# ESP32C3 register map
File version: 1.0
CPU: RISC-V RV32IMC single-core 1, little endian, no MPU, FPU, 3 interrupt priority bits
Registers are 32-bit, read-write, reset 0x0 unless marked. A register's access mark holds for its fields unless they carry their own. Offsets are from the block's base; [hi:lo] are bit positions; {n}, {i} and the like mark numbered series.

## EFUSE
Base 0x60008800
0x00 EFUSE_PGM_DATA0
  [31:0] EFUSE_WR_DIS
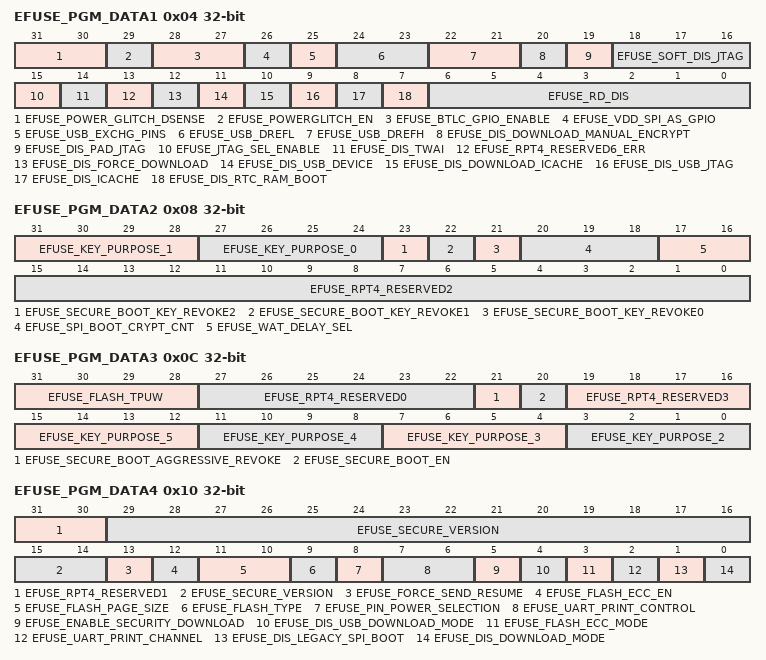
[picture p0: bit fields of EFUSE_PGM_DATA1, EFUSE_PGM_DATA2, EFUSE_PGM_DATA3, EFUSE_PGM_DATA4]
0x04 EFUSE_PGM_DATA1 access per field
  [31:30] EFUSE_POWER_GLITCH_DSENSE rw, [29] EFUSE_POWERGLITCH_EN rw, [28:27] EFUSE_BTLC_GPIO_ENABLE rw, [26] EFUSE_VDD_SPI_AS_GPIO rw, [25] EFUSE_USB_EXCHG_PINS rw, [24:23] EFUSE_USB_DREFL rw, [22:21] EFUSE_USB_DREFH rw, [20] EFUSE_DIS_DOWNLOAD_MANUAL_ENCRYPT rw, [19] EFUSE_DIS_PAD_JTAG rw, [18:16] EFUSE_SOFT_DIS_JTAG rw, [15] EFUSE_JTAG_SEL_ENABLE rw, [14] EFUSE_DIS_TWAI rw, [13] EFUSE_RPT4_RESERVED6_ERR ro, [12] EFUSE_DIS_FORCE_DOWNLOAD rw, [11] EFUSE_DIS_USB_DEVICE rw, [10] EFUSE_DIS_DOWNLOAD_ICACHE rw, [9] EFUSE_DIS_USB_JTAG rw, [8] EFUSE_DIS_ICACHE rw, [7] EFUSE_DIS_RTC_RAM_BOOT rw, [6:0] EFUSE_RD_DIS rw
0x08 EFUSE_PGM_DATA2 access per field
  [31:28] EFUSE_KEY_PURPOSE_1 rw, [27:24] EFUSE_KEY_PURPOSE_0 rw, [23] EFUSE_SECURE_BOOT_KEY_REVOKE2 rw, [22] EFUSE_SECURE_BOOT_KEY_REVOKE1 rw, [21] EFUSE_SECURE_BOOT_KEY_REVOKE0 rw, [20:18] EFUSE_SPI_BOOT_CRYPT_CNT rw, [17:16] EFUSE_WAT_DELAY_SEL rw, [15:0] EFUSE_RPT4_RESERVED2 ro
0x0C EFUSE_PGM_DATA3 access per field
  [31:28] EFUSE_FLASH_TPUW rw, [27:22] EFUSE_RPT4_RESERVED0 ro, [21] EFUSE_SECURE_BOOT_AGGRESSIVE_REVOKE rw, [20] EFUSE_SECURE_BOOT_EN rw, [19:16] EFUSE_RPT4_RESERVED3 ro, [4n-5:4n-8] EFUSE_KEY_PURPOSE_{n} rw (n=2..5)
0x10 EFUSE_PGM_DATA4 access per field
  [31:30] EFUSE_RPT4_RESERVED1 ro, [29:14] EFUSE_SECURE_VERSION rw, [13] EFUSE_FORCE_SEND_RESUME rw, [12] EFUSE_FLASH_ECC_EN rw, [11:10] EFUSE_FLASH_PAGE_SIZE rw, [9] EFUSE_FLASH_TYPE rw, [8] EFUSE_PIN_POWER_SELECTION rw, [7:6] EFUSE_UART_PRINT_CONTROL rw, [5] EFUSE_ENABLE_SECURITY_DOWNLOAD rw, [4] EFUSE_DIS_USB_DOWNLOAD_MODE rw, [3] EFUSE_FLASH_ECC_MODE rw, [2] EFUSE_UART_PRINT_CHANNEL rw, [1] EFUSE_DIS_LEGACY_SPI_BOOT rw, [0] EFUSE_DIS_DOWNLOAD_MODE rw
0x14 EFUSE_PGM_DATA5 ro
  [23:0] EFUSE_RPT4_RESERVED4
0x18 EFUSE_PGM_DATA6
  [31:0] EFUSE_PGM_DATA_6
0x1C EFUSE_PGM_DATA7
  [31:0] EFUSE_PGM_DATA_7
{0x20+4i} EFUSE_PGM_CHECK_VALUE{i} (i=0..2)
  [31:0] EFUSE_PGM_RS_DATA_{i}
0x2C EFUSE_RD_WR_DIS ro
  [31:0] EFUSE_WR_DIS
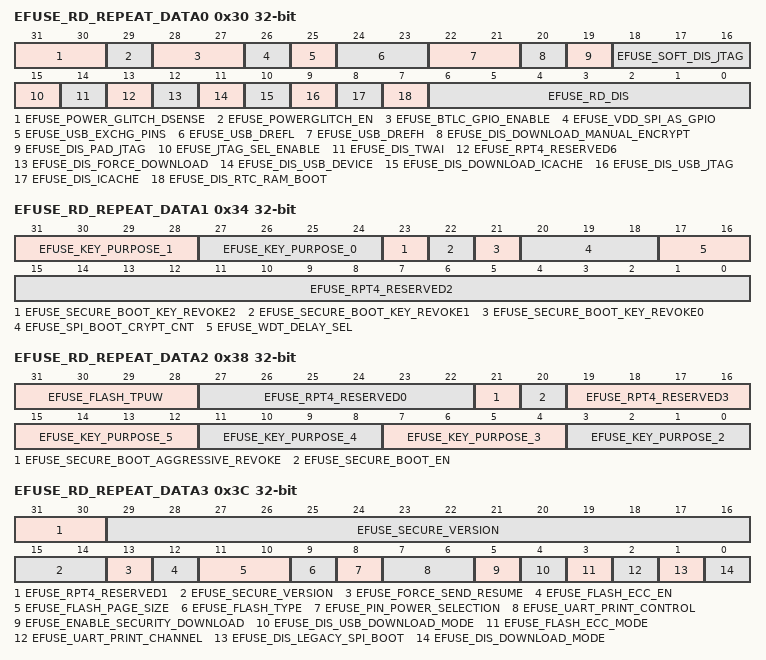
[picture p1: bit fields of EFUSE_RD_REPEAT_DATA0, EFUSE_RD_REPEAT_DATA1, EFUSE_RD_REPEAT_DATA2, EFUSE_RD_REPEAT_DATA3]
0x30 EFUSE_RD_REPEAT_DATA0 ro
  [31:30] EFUSE_POWER_GLITCH_DSENSE, [29] EFUSE_POWERGLITCH_EN, [28:27] EFUSE_BTLC_GPIO_ENABLE, [26] EFUSE_VDD_SPI_AS_GPIO, [25] EFUSE_USB_EXCHG_PINS, [24:23] EFUSE_USB_DREFL, [22:21] EFUSE_USB_DREFH, [20] EFUSE_DIS_DOWNLOAD_MANUAL_ENCRYPT, [19] EFUSE_DIS_PAD_JTAG, [18:16] EFUSE_SOFT_DIS_JTAG, [15] EFUSE_JTAG_SEL_ENABLE, [14] EFUSE_DIS_TWAI, [13] EFUSE_RPT4_RESERVED6, [12] EFUSE_DIS_FORCE_DOWNLOAD, [11] EFUSE_DIS_USB_DEVICE, [10] EFUSE_DIS_DOWNLOAD_ICACHE, [9] EFUSE_DIS_USB_JTAG, [8] EFUSE_DIS_ICACHE, [7] EFUSE_DIS_RTC_RAM_BOOT, [6:0] EFUSE_RD_DIS
0x34 EFUSE_RD_REPEAT_DATA1 ro
  [31:28] EFUSE_KEY_PURPOSE_1, [27:24] EFUSE_KEY_PURPOSE_0, [23] EFUSE_SECURE_BOOT_KEY_REVOKE2, [22] EFUSE_SECURE_BOOT_KEY_REVOKE1, [21] EFUSE_SECURE_BOOT_KEY_REVOKE0, [20:18] EFUSE_SPI_BOOT_CRYPT_CNT, [17:16] EFUSE_WDT_DELAY_SEL, [15:0] EFUSE_RPT4_RESERVED2
0x38 EFUSE_RD_REPEAT_DATA2 ro
  [31:28] EFUSE_FLASH_TPUW, [27:22] EFUSE_RPT4_RESERVED0, [21] EFUSE_SECURE_BOOT_AGGRESSIVE_REVOKE, [20] EFUSE_SECURE_BOOT_EN, [19:16] EFUSE_RPT4_RESERVED3, [4n-5:4n-8] EFUSE_KEY_PURPOSE_{n} (n=2..5)
0x3C EFUSE_RD_REPEAT_DATA3 ro
  [31:30] EFUSE_RPT4_RESERVED1, [29:14] EFUSE_SECURE_VERSION, [13] EFUSE_FORCE_SEND_RESUME, [12] EFUSE_FLASH_ECC_EN, [11:10] EFUSE_FLASH_PAGE_SIZE, [9] EFUSE_FLASH_TYPE, [8] EFUSE_PIN_POWER_SELECTION, [7:6] EFUSE_UART_PRINT_CONTROL, [5] EFUSE_ENABLE_SECURITY_DOWNLOAD, [4] EFUSE_DIS_USB_DOWNLOAD_MODE, [3] EFUSE_FLASH_ECC_MODE, [2] EFUSE_UART_PRINT_CHANNEL, [1] EFUSE_DIS_LEGACY_SPI_BOOT, [0] EFUSE_DIS_DOWNLOAD_MODE
0x40 EFUSE_RD_REPEAT_DATA4 ro
  [23:0] EFUSE_RPT4_RESERVED4
0x44 EFUSE_RD_MAC_SPI_SYS_0 ro
  [31:0] EFUSE_MAC_0
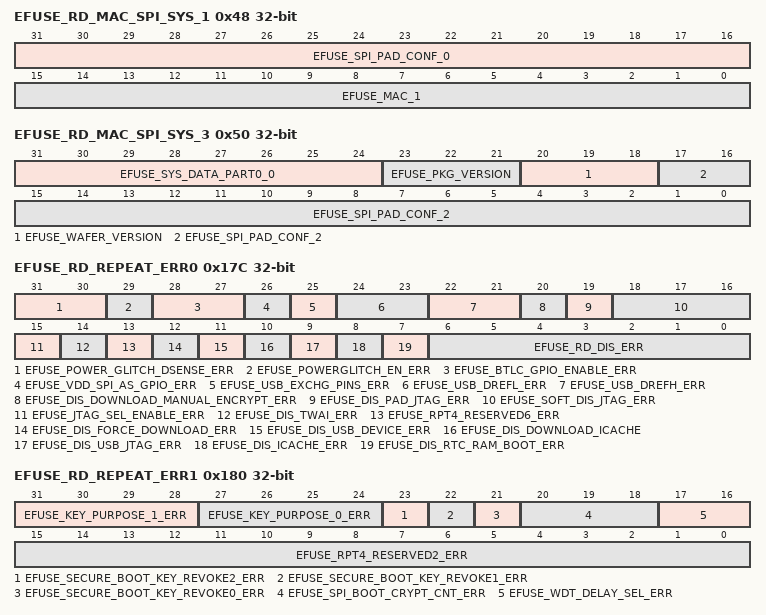
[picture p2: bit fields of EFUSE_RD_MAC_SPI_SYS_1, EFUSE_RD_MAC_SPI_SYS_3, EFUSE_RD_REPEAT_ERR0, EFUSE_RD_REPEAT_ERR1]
0x48 EFUSE_RD_MAC_SPI_SYS_1 ro
  [31:16] EFUSE_SPI_PAD_CONF_0, [15:0] EFUSE_MAC_1
0x4C EFUSE_RD_MAC_SPI_SYS_2 ro
  [31:0] EFUSE_SPI_PAD_CONF_1
0x50 EFUSE_RD_MAC_SPI_SYS_3 ro
  [31:24] EFUSE_SYS_DATA_PART0_0, [23:21] EFUSE_PKG_VERSION, [20:18] EFUSE_WAFER_VERSION, [17:0] EFUSE_SPI_PAD_CONF_2
0x54 EFUSE_RD_MAC_SPI_SYS_4 ro
  [31:0] EFUSE_SYS_DATA_PART0_1
0x58 EFUSE_RD_MAC_SPI_SYS_5 ro
  [31:0] EFUSE_SYS_DATA_PART0_2
{0x5C+4i} EFUSE_RD_SYS_PART1_DATA{i} ro (i=0..7)
  [31:0] EFUSE_SYS_DATA_PART1_{i}
{0x7C+4i} EFUSE_RD_USR_DATA{i} ro (i=0..7)
  [31:0] EFUSE_USR_DATA{i}
{0x9C+4i} EFUSE_RD_KEY0_DATA{i} ro (i=0..7)
  [31:0] EFUSE_KEY0_DATA{i}
{0xBC+4i} EFUSE_RD_KEY1_DATA{i} ro (i=0..7)
  [31:0] EFUSE_KEY1_DATA{i}
{0xDC+4i} EFUSE_RD_KEY2_DATA{i} ro (i=0..7)
  [31:0] EFUSE_KEY2_DATA{i}
{0xFC+4i} EFUSE_RD_KEY3_DATA{i} ro (i=0..7)
  [31:0] EFUSE_KEY3_DATA{i}
{0x11C+4i} EFUSE_RD_KEY4_DATA{i} ro (i=0..7)
  [31:0] EFUSE_KEY4_DATA{i}
{0x13C+4i} EFUSE_RD_KEY5_DATA{i} ro (i=0..7)
  [31:0] EFUSE_KEY5_DATA{i}
{0x15C+4i} EFUSE_RD_SYS_PART2_DATA{i} ro (i=0..7)
  [31:0] EFUSE_SYS_DATA_PART2_{i}
0x17C EFUSE_RD_REPEAT_ERR0 ro
  [31:30] EFUSE_POWER_GLITCH_DSENSE_ERR, [29] EFUSE_POWERGLITCH_EN_ERR, [28:27] EFUSE_BTLC_GPIO_ENABLE_ERR, [26] EFUSE_VDD_SPI_AS_GPIO_ERR, [25] EFUSE_USB_EXCHG_PINS_ERR, [24:23] EFUSE_USB_DREFL_ERR, [22:21] EFUSE_USB_DREFH_ERR, [20] EFUSE_DIS_DOWNLOAD_MANUAL_ENCRYPT_ERR, [19] EFUSE_DIS_PAD_JTAG_ERR, [18:16] EFUSE_SOFT_DIS_JTAG_ERR, [15] EFUSE_JTAG_SEL_ENABLE_ERR, [14] EFUSE_DIS_TWAI_ERR, [13] EFUSE_RPT4_RESERVED6_ERR, [12] EFUSE_DIS_FORCE_DOWNLOAD_ERR, [11] EFUSE_DIS_USB_DEVICE_ERR, [10] EFUSE_DIS_DOWNLOAD_ICACHE, [9] EFUSE_DIS_USB_JTAG_ERR, [8] EFUSE_DIS_ICACHE_ERR, [7] EFUSE_DIS_RTC_RAM_BOOT_ERR, [6:0] EFUSE_RD_DIS_ERR
0x180 EFUSE_RD_REPEAT_ERR1 ro
  [31:28] EFUSE_KEY_PURPOSE_1_ERR, [27:24] EFUSE_KEY_PURPOSE_0_ERR, [23] EFUSE_SECURE_BOOT_KEY_REVOKE2_ERR, [22] EFUSE_SECURE_BOOT_KEY_REVOKE1_ERR, [21] EFUSE_SECURE_BOOT_KEY_REVOKE0_ERR, [20:18] EFUSE_SPI_BOOT_CRYPT_CNT_ERR, [17:16] EFUSE_WDT_DELAY_SEL_ERR, [15:0] EFUSE_RPT4_RESERVED2_ERR
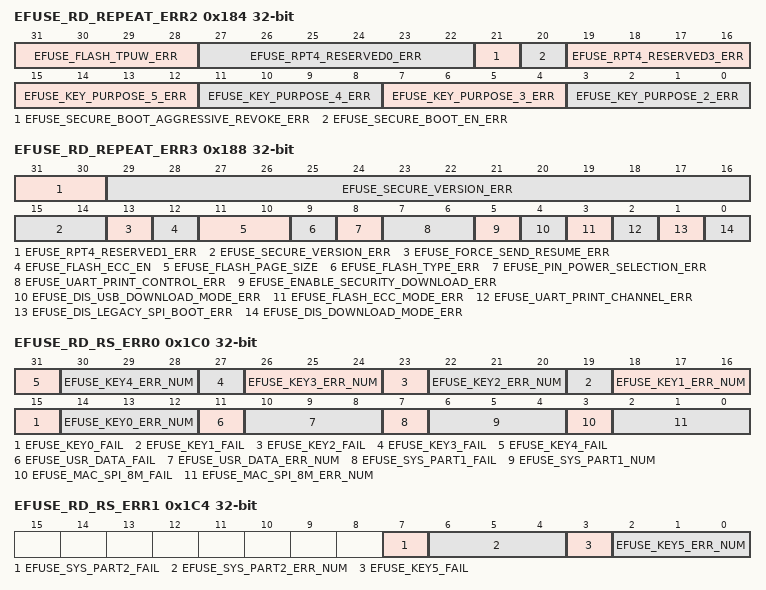
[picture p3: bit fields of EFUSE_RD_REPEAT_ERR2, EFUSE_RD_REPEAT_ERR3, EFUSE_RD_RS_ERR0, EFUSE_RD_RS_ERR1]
0x184 EFUSE_RD_REPEAT_ERR2 ro
  [31:28] EFUSE_FLASH_TPUW_ERR, [27:22] EFUSE_RPT4_RESERVED0_ERR, [21] EFUSE_SECURE_BOOT_AGGRESSIVE_REVOKE_ERR, [20] EFUSE_SECURE_BOOT_EN_ERR, [19:16] EFUSE_RPT4_RESERVED3_ERR, [4n-5:4n-8] EFUSE_KEY_PURPOSE_{n}_ERR (n=2..5)
0x188 EFUSE_RD_REPEAT_ERR3 ro
  [31:30] EFUSE_RPT4_RESERVED1_ERR, [29:14] EFUSE_SECURE_VERSION_ERR, [13] EFUSE_FORCE_SEND_RESUME_ERR, [12] EFUSE_FLASH_ECC_EN, [11:10] EFUSE_FLASH_PAGE_SIZE, [9] EFUSE_FLASH_TYPE_ERR, [8] EFUSE_PIN_POWER_SELECTION_ERR, [7:6] EFUSE_UART_PRINT_CONTROL_ERR, [5] EFUSE_ENABLE_SECURITY_DOWNLOAD_ERR, [4] EFUSE_DIS_USB_DOWNLOAD_MODE_ERR, [3] EFUSE_FLASH_ECC_MODE_ERR, [2] EFUSE_UART_PRINT_CHANNEL_ERR, [1] EFUSE_DIS_LEGACY_SPI_BOOT_ERR, [0] EFUSE_DIS_DOWNLOAD_MODE_ERR
0x190 EFUSE_RD_REPEAT_ERR4 ro
  [23:0] EFUSE_RPT4_RESERVED4_ERR
0x1C0 EFUSE_RD_RS_ERR0 ro
  [4n+15] EFUSE_KEY{n}_FAIL (n=0..4), [4n+14:4n+12] EFUSE_KEY{n}_ERR_NUM (n=0..4), [11] EFUSE_USR_DATA_FAIL, [10:8] EFUSE_USR_DATA_ERR_NUM, [7] EFUSE_SYS_PART1_FAIL, [6:4] EFUSE_SYS_PART1_NUM, [3] EFUSE_MAC_SPI_8M_FAIL, [2:0] EFUSE_MAC_SPI_8M_ERR_NUM
0x1C4 EFUSE_RD_RS_ERR1 ro
  [7] EFUSE_SYS_PART2_FAIL, [6:4] EFUSE_SYS_PART2_ERR_NUM, [3] EFUSE_KEY5_FAIL, [2:0] EFUSE_KEY5_ERR_NUM
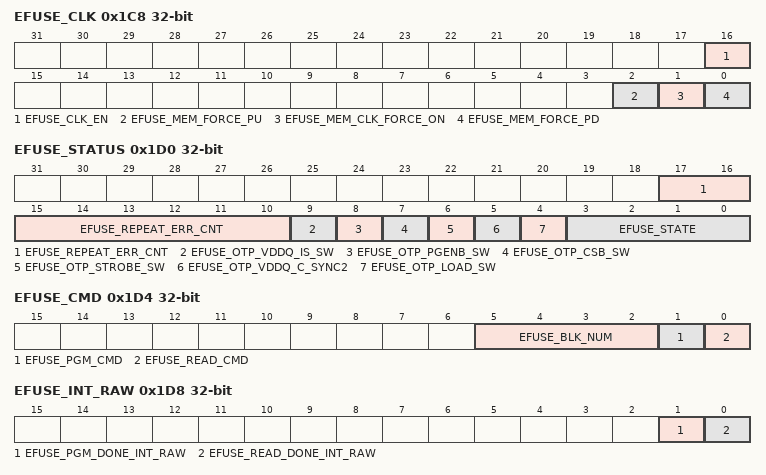
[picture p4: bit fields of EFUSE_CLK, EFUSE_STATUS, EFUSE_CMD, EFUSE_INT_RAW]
0x1C8 EFUSE_CLK
  [16] EFUSE_CLK_EN, [2] EFUSE_MEM_FORCE_PU, [1] EFUSE_MEM_CLK_FORCE_ON, [0] EFUSE_MEM_FORCE_PD
0x1CC EFUSE_CONF
  [15:0] EFUSE_OP_CODE
0x1D0 EFUSE_STATUS ro
  [17:10] EFUSE_REPEAT_ERR_CNT, [9] EFUSE_OTP_VDDQ_IS_SW, [8] EFUSE_OTP_PGENB_SW, [7] EFUSE_OTP_CSB_SW, [6] EFUSE_OTP_STROBE_SW, [5] EFUSE_OTP_VDDQ_C_SYNC2, [4] EFUSE_OTP_LOAD_SW, [3:0] EFUSE_STATE
0x1D4 EFUSE_CMD
  [5:2] EFUSE_BLK_NUM, [1] EFUSE_PGM_CMD, [0] EFUSE_READ_CMD
0x1D8 EFUSE_INT_RAW ro
  [1] EFUSE_PGM_DONE_INT_RAW, [0] EFUSE_READ_DONE_INT_RAW
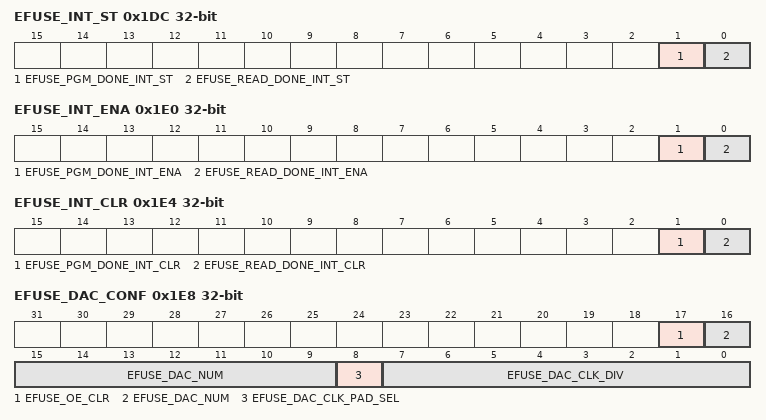
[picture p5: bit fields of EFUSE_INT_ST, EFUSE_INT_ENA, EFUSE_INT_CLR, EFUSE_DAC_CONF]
0x1DC EFUSE_INT_ST ro
  [1] EFUSE_PGM_DONE_INT_ST, [0] EFUSE_READ_DONE_INT_ST
0x1E0 EFUSE_INT_ENA
  [1] EFUSE_PGM_DONE_INT_ENA, [0] EFUSE_READ_DONE_INT_ENA
0x1E4 EFUSE_INT_CLR wo
  [1] EFUSE_PGM_DONE_INT_CLR, [0] EFUSE_READ_DONE_INT_CLR
0x1E8 EFUSE_DAC_CONF
  [17] EFUSE_OE_CLR, [16:9] EFUSE_DAC_NUM, [8] EFUSE_DAC_CLK_PAD_SEL, [7:0] EFUSE_DAC_CLK_DIV
0x1EC EFUSE_RD_TIM_CONF
  [31:24] EFUSE_READ_INIT_NUM
0x1F0 EFUSE_WR_TIM_CONF1
  [23:8] EFUSE_PWR_ON_NUM
0x1F4 EFUSE_WR_TIM_CONF2
  [15:0] EFUSE_PWR_OFF_NUM
0x1FC EFUSE_DATE
  [27:0] EFUSE_DATE
